AUTOSAR XML (schema 314)
package /ComponentType
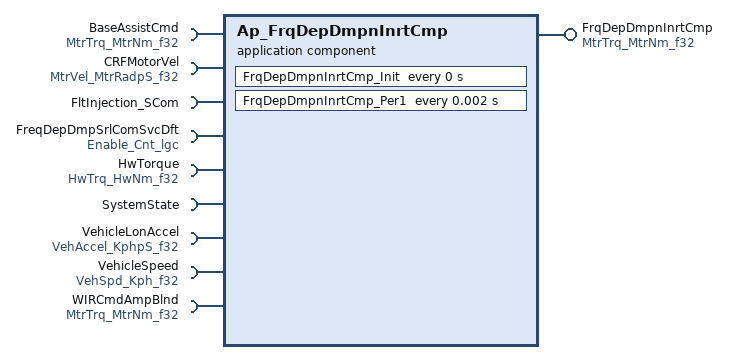
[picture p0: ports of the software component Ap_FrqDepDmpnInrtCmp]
  application software component type Ap_FrqDepDmpnInrtCmp
    provide port FrqDepDmpnInrtCmp: unqueued-sender-com-spec{data-element=MtrNm_f32, can-invalidate=false, init-value=D_ZERO_ULS_F32}, provided-interface=MtrTrq_MtrNm_f32
    9 x require port:
      BaseAssistCmd: unqueued-receiver-com-spec{data-element=MtrNm_f32, init-value=D_ZERO_ULS_F32}, required-interface=MtrTrq_MtrNm_f32
      CRFMotorVel: unqueued-receiver-com-spec{data-element=MtrRadpS_f32, init-value=D_ZERO_ULS_F32}, required-interface=MtrVel_MtrRadpS_f32
      FltInjection_SCom: client-com-spec=FltInjection, required-interface=FltInjection_SCom
      FreqDepDmpSrlComSvcDft: unqueued-receiver-com-spec{data-element=Cnt_lgc, init-value=D_FALSE_CNT_LGC}, required-interface=Enable_Cnt_lgc
      HwTorque: unqueued-receiver-com-spec{data-element=HwNm_f32, init-value=D_ZERO_ULS_F32}, required-interface=HwTrq_HwNm_f32
      SystemState: required-interface=SystemState
      VehicleLonAccel: unqueued-receiver-com-spec{data-element=KphpS_f32, init-value=D_ZERO_ULS_F32}, required-interface=VehAccel_KphpS_f32
      VehicleSpeed: unqueued-receiver-com-spec{data-element=Kph_f32, init-value=D_ZERO_ULS_F32}, required-interface=VehSpd_Kph_f32
      WIRCmdAmpBlnd: unqueued-receiver-com-spec{data-element=MtrNm_f32, init-value=D_ZERO_ULS_F32}, required-interface=MtrTrq_MtrNm_f32
  internal behavior Ap_FrqDepDmpnInrtCmp_InternalBehavior: component=Ap_FrqDepDmpnInrtCmp
    timing event FrqDepDmpnInrtCmp_InitEvent: start-on-event=FrqDepDmpnInrtCmp_Init, period=0
    timing event TMT_FrqDepDmpnInrtCmp_Per1: mode-dependency=dependent-on-mode=SystemState.Mode.DISABLE, start-on-event=FrqDepDmpnInrtCmp_Per1, period=0.002
    port-api-options:
      enable-take-address=false, indirect-api=false, port=BaseAssistCmd
      enable-take-address=false, indirect-api=false, port=CRFMotorVel
      enable-take-address=false, indirect-api=false, port=FltInjection_SCom
      enable-take-address=false, indirect-api=false, port=FreqDepDmpSrlComSvcDft
      enable-take-address=false, indirect-api=false, port=FrqDepDmpnInrtCmp
      enable-take-address=false, indirect-api=false, port=HwTorque
      enable-take-address=false, indirect-api=false, port=SystemState
      enable-take-address=false, indirect-api=false, port=VehicleLonAccel
      enable-take-address=false, indirect-api=false, port=VehicleSpeed
      enable-take-address=false, indirect-api=false, port=WIRCmdAmpBlnd
    runnable FrqDepDmpnInrtCmp_Init
    runnable FrqDepDmpnInrtCmp_Per1
      7 x data read access:
        READ_BaseAssistCmd_MtrNm_f32: data-element=BaseAssistCmd.MtrNm_f32
        READ_CRFMotorVel_MtrRadpS_f32: data-element=CRFMotorVel.MtrRadpS_f32
        READ_FreqDepDmpSrlComSvcDft_Cnt_lgc: data-element=FreqDepDmpSrlComSvcDft.Cnt_lgc
        READ_HwTorque_HwNm_f32: data-element=HwTorque.HwNm_f32
        READ_VehicleLonAccel_KphpS_f32: data-element=VehicleLonAccel.KphpS_f32
        READ_VehicleSpeed_Kph_f32: data-element=VehicleSpeed.Kph_f32
        READ_WIRCmdAmpBlnd_MtrNm_f32: data-element=WIRCmdAmpBlnd.MtrNm_f32
      data write access WRITE_FrqDepDmpnInrtCmp_MtrNm_f32: data-element=FrqDepDmpnInrtCmp.MtrNm_f32
      sync call SC_FltInjection_SCom_FltInjection: operation=FltInjection_SCom.FltInjection, timeout=0
  swc implementation Ap_FrqDepDmpnInrtCmp_Implementation: behavior=Ap_FrqDepDmpnInrtCmp_InternalBehavior
    code-descriptors:
      code Code: type=SRC
